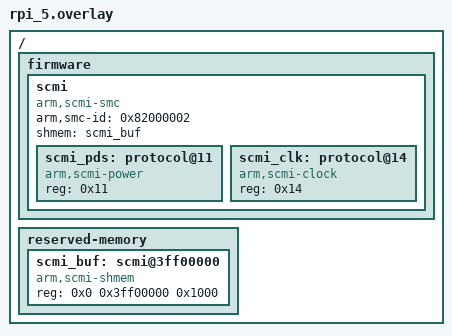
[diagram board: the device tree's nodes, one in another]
/*
 * Copyright (c) 2026 EPAM Systems
 *
 * SPDX-License-Identifier: Apache-2.0
 */

/ {
	firmware {
		scmi {
			compatible = "arm,scmi-smc";
			arm,smc-id = <0x82000002>;
			#address-cells = <1>;
			#size-cells = <0>;
			shmem = <&scmi_buf>;

			scmi_pds: protocol@11 {
				compatible = "arm,scmi-power";
				reg = <0x11>;
				#power-domain-cells = <1>;
		  	};

			scmi_clk: protocol@14 {
				compatible = "arm,scmi-clock";
				reg = <0x14>;
				#clock-cells = <1>;
			};
		};
	};

	reserved-memory {
		#address-cells = <2>;
		#size-cells = <1>;
		ranges;

		scmi_buf: scmi@3ff00000 {
			compatible = "arm,scmi-shmem";
			reg = <0x0 0x3ff00000 0x1000>;
		};
	};
};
